# MCU_PADCFG_CTRL0_CFG0 register map
Vendor: Texas Instruments
Peripheral module from a debugger description file (folder J722S).
Registers are 32-bit, read-only, reset 0x0 unless marked. A register's access mark holds for its fields unless they carry their own. Offsets are as the file gives them; lines under a group give offsets from that group; [hi:lo] are bit positions; {n}, {i} and the like mark numbered series; 'fields as' and 'values as' point back to an identical list; <NAME> marks a mode.

## MCU_PADCFG_CTRL0_CFG0
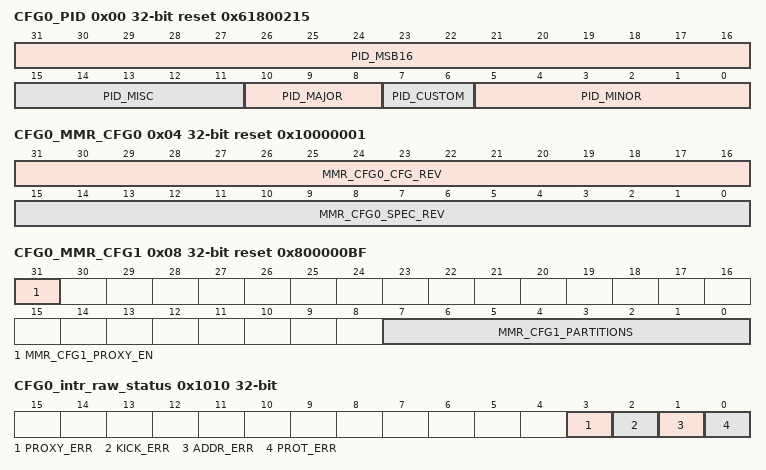
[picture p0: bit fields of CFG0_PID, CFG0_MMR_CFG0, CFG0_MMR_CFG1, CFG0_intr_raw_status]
0x00 CFG0_PID reset 0x61800215
  [31:16] PID_MSB16, [15:11] PID_MISC, [10:8] PID_MAJOR, [7:6] PID_CUSTOM, [5:0] PID_MINOR
0x04 CFG0_MMR_CFG0 reset 0x10000001
  [31:16] MMR_CFG0_CFG_REV — Major configuration release
  [15:0] MMR_CFG0_SPEC_REV — Minor spec-only revision. Doesn't change RTL release
0x08 CFG0_MMR_CFG1 reset 0x800000BF
  [31] MMR_CFG1_PROXY_EN — Proxy addressing enabled
  [7:0] MMR_CFG1_PARTITIONS — Indicates present partitions
0x1008 CFG0_LOCK0_KICK0 rw
  [31:0] LOCK0_KICK0 — - KICK0 component
0x100C CFG0_LOCK0_KICK1 rw
  [31:0] LOCK0_KICK1 — - KICK1 component
0x1010 CFG0_intr_raw_status access not given
  [3] PROXY_ERR — Proxy0 access violation error. Raw status is read. Write a 1 to set the status. Writing a 0 has no effect. (access R/W1TS)
  [2] KICK_ERR — Kick access violation error. Raw status is read. Write a 1 to set the status. Writing a 0 has no effect. (access R/W1TS)
  [1] ADDR_ERR — Addressing violation error. Raw status is read. Write a 1 to set the status. Writing a 0 has no effect. (access R/W1TS)
  [0] PROT_ERR — Protection violation error. Raw status is read. Write a 1 to set the status. Writing a 0 has no effect. (access R/W1TS)
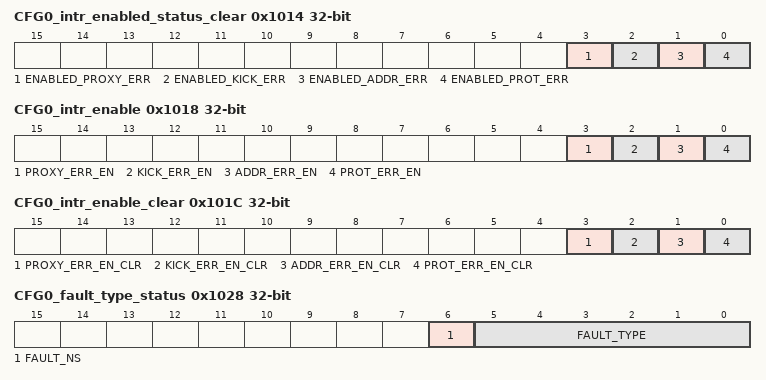
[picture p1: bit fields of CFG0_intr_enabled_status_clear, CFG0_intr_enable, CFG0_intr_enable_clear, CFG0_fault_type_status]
0x1014 CFG0_intr_enabled_status_clear access not given
  [3] ENABLED_PROXY_ERR — Proxy0 access violation error. Enabled status is read. Write a 1 to clear the status. Writing a 0 has no effect. (access R/W1TC)
  [2] ENABLED_KICK_ERR — Kick access violation error. Enabled status is read. Write a 1 to clear the status. Writing a 0 has no effect. (access R/W1TC)
  [1] ENABLED_ADDR_ERR — Addressing violation error. Enabled status is read. Write a 1 to clear the status. Writing a 0 has no effect. (access R/W1TC)
  [0] ENABLED_PROT_ERR — Protection violation error. Enabled status is read. Write a 1 to clear the status. Writing a 0 has no effect. (access R/W1TC)
0x1018 CFG0_intr_enable access not given
  [3] PROXY_ERR_EN — Proxy0 access violation error enable. Write a 1 to set the enable. Writing a 0 has no effect. (access R/W1TS)
  [2] KICK_ERR_EN — Kick access violation error enable. Write a 1 to set the enable. Writing a 0 has no effect. (access R/W1TS)
  [1] ADDR_ERR_EN — Addressing violation error enable. Write a 1 to set the enable. Writing a 0 has no effect. (access R/W1TS)
  [0] PROT_ERR_EN — Protection violation error enable. Write a 1 to set the enable. Writing a 0 has no effect. (access R/W1TS)
0x101C CFG0_intr_enable_clear access not given
  [3] PROXY_ERR_EN_CLR — Proxy0 access violation error enable clear. Write a 1 to clear the enable. Writing a 0 has no effect. (access R/W1TC)
  [2] KICK_ERR_EN_CLR — Kick access violation error enable clear. Write a 1 to clear the enable. Writing a 0 has no effect. (access R/W1TC)
  [1] ADDR_ERR_EN_CLR — Addressing violation error enable clear. Write a 1 to clear the enable. Writing a 0 has no effect. (access R/W1TC)
  [0] PROT_ERR_EN_CLR — Protection violation error enable clear. Write a 1 to clear the enable. Writing a 0 has no effect. (access R/W1TC)
0x1020 CFG0_eoi rw
  [7:0] EOI_VECTOR — EOI vector value. Write this with interrupt distribution value in the chip.
0x1024 CFG0_fault_address
  [31:0] FAULT_ADDR — Fault Address.
0x1028 CFG0_fault_type_status
  [6] FAULT_NS — Non-secure access.
  [5:0] FAULT_TYPE — Fault Type 10_0000 = Supervisor read fault - priv = 1 dir = 1 dtype != 1 01_0000 = Supervisor write fault - priv = 1 dir = 0 00_1000 = Supervisor execute fault - priv = 1 dir = 1 dtype = 1 00_0100 = User read fault - priv = 0 dir = 1 dtype = 1 00_0010 = User write fault - priv = 0 dir = 0 00_0001 = User execute fault - priv = 0 dir = 1 dtype = 1 00_0000 = No fault
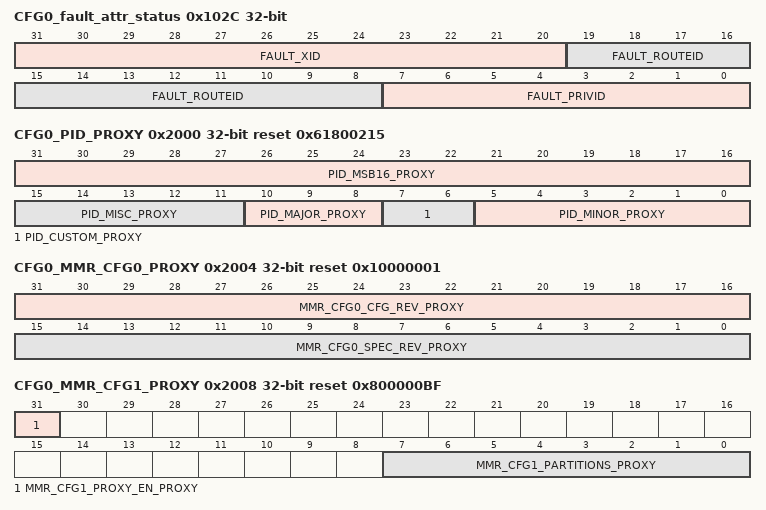
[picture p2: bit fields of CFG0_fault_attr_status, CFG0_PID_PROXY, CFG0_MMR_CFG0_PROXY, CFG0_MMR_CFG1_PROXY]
0x102C CFG0_fault_attr_status
  [31:20] FAULT_XID — XID.
  [19:8] FAULT_ROUTEID — Route ID.
  [7:0] FAULT_PRIVID — Privilege ID.
0x1030 CFG0_fault_clear wo
  [0] FAULT_CLR — Fault clear. Writing a 1 clears the current fault. Writing a 0 has no effect.
0x1100 CFG0_CLAIMREG_P0_R0_READONLY
  [31:0] CLAIMREG_P0_R0_READONLY — Claim bits for Partition 0
0x2000 CFG0_PID_PROXY reset 0x61800215
  [31:16] PID_MSB16_PROXY, [15:11] PID_MISC_PROXY, [10:8] PID_MAJOR_PROXY, [7:6] PID_CUSTOM_PROXY, [5:0] PID_MINOR_PROXY
0x2004 CFG0_MMR_CFG0_PROXY reset 0x10000001
  [31:16] MMR_CFG0_CFG_REV_PROXY — Major configuration release
  [15:0] MMR_CFG0_SPEC_REV_PROXY — Minor spec-only revision. Doesn't change RTL release
0x2008 CFG0_MMR_CFG1_PROXY reset 0x800000BF
  [31] MMR_CFG1_PROXY_EN_PROXY — Proxy addressing enabled
  [7:0] MMR_CFG1_PARTITIONS_PROXY — Indicates present partitions
0x3008 CFG0_LOCK0_KICK0_PROXY rw
  [31:0] LOCK0_KICK0_PROXY — - KICK0 component
0x300C CFG0_LOCK0_KICK1_PROXY rw
  [31:0] LOCK0_KICK1_PROXY — - KICK1 component
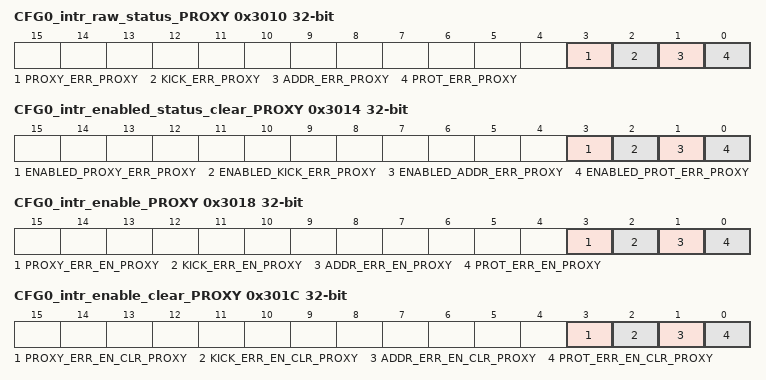
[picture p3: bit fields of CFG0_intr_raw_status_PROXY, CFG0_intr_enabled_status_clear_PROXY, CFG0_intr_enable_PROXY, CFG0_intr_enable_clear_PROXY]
0x3010 CFG0_intr_raw_status_PROXY access not given
  [3] PROXY_ERR_PROXY — Proxy0 access violation error. Raw status is read. Write a 1 to set the status. Writing a 0 has no effect. (access R/W1TS)
  [2] KICK_ERR_PROXY — Kick access violation error. Raw status is read. Write a 1 to set the status. Writing a 0 has no effect. (access R/W1TS)
  [1] ADDR_ERR_PROXY — Addressing violation error. Raw status is read. Write a 1 to set the status. Writing a 0 has no effect. (access R/W1TS)
  [0] PROT_ERR_PROXY — Protection violation error. Raw status is read. Write a 1 to set the status. Writing a 0 has no effect. (access R/W1TS)
0x3014 CFG0_intr_enabled_status_clear_PROXY access not given
  [3] ENABLED_PROXY_ERR_PROXY — Proxy0 access violation error. Enabled status is read. Write a 1 to clear the status. Writing a 0 has no effect. (access R/W1TC)
  [2] ENABLED_KICK_ERR_PROXY — Kick access violation error. Enabled status is read. Write a 1 to clear the status. Writing a 0 has no effect. (access R/W1TC)
  [1] ENABLED_ADDR_ERR_PROXY — Addressing violation error. Enabled status is read. Write a 1 to clear the status. Writing a 0 has no effect. (access R/W1TC)
  [0] ENABLED_PROT_ERR_PROXY — Protection violation error. Enabled status is read. Write a 1 to clear the status. Writing a 0 has no effect. (access R/W1TC)
0x3018 CFG0_intr_enable_PROXY access not given
  [3] PROXY_ERR_EN_PROXY — Proxy0 access violation error enable. Write a 1 to set the enable. Writing a 0 has no effect. (access R/W1TS)
  [2] KICK_ERR_EN_PROXY — Kick access violation error enable. Write a 1 to set the enable. Writing a 0 has no effect. (access R/W1TS)
  [1] ADDR_ERR_EN_PROXY — Addressing violation error enable. Write a 1 to set the enable. Writing a 0 has no effect. (access R/W1TS)
  [0] PROT_ERR_EN_PROXY — Protection violation error enable. Write a 1 to set the enable. Writing a 0 has no effect. (access R/W1TS)
0x301C CFG0_intr_enable_clear_PROXY access not given
  [3] PROXY_ERR_EN_CLR_PROXY — Proxy0 access violation error enable clear. Write a 1 to clear the enable. Writing a 0 has no effect. (access R/W1TC)
  [2] KICK_ERR_EN_CLR_PROXY — Kick access violation error enable clear. Write a 1 to clear the enable. Writing a 0 has no effect. (access R/W1TC)
  [1] ADDR_ERR_EN_CLR_PROXY — Addressing violation error enable clear. Write a 1 to clear the enable. Writing a 0 has no effect. (access R/W1TC)
  [0] PROT_ERR_EN_CLR_PROXY — Protection violation error enable clear. Write a 1 to clear the enable. Writing a 0 has no effect. (access R/W1TC)
0x3020 CFG0_eoi_PROXY rw
  [7:0] EOI_VECTOR_PROXY — EOI vector value. Write this with interrupt distribution value in the chip.
0x3024 CFG0_fault_address_PROXY
  [31:0] FAULT_ADDR_PROXY — Fault Address.
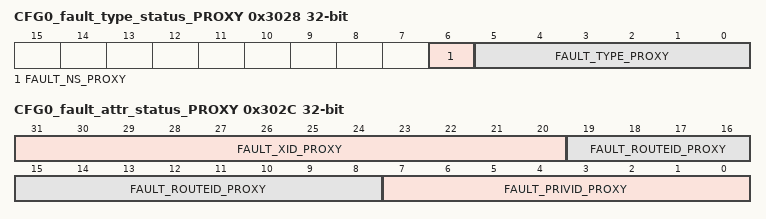
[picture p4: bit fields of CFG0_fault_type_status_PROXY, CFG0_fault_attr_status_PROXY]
0x3028 CFG0_fault_type_status_PROXY
  [6] FAULT_NS_PROXY — Non-secure access.
  [5:0] FAULT_TYPE_PROXY — Fault Type 10_0000 = Supervisor read fault - priv = 1 dir = 1 dtype != 1 01_0000 = Supervisor write fault - priv = 1 dir = 0 00_1000 = Supervisor execute fault - priv = 1 dir = 1 dtype = 1 00_0100 = User read fault - priv = 0 dir = 1 dtype = 1 00_0010 = User write fault - priv = 0 dir = 0 00_0001 = User execute fault - priv = 0 dir = 1 dtype = 1 00_0000 = No fault
0x302C CFG0_fault_attr_status_PROXY
  [31:20] FAULT_XID_PROXY — XID.
  [19:8] FAULT_ROUTEID_PROXY — Route ID.
  [7:0] FAULT_PRIVID_PROXY — Privilege ID.
0x3030 CFG0_fault_clear_PROXY wo
  [0] FAULT_CLR_PROXY — Fault clear. Writing a 1 clears the current fault. Writing a 0 has no effect.
0x3100 CFG0_CLAIMREG_P0_R0 rw
  [31:0] CLAIMREG_P0_R0 — Claim bits for Partition 0
0x5008 CFG0_LOCK1_KICK0 rw
  [31:0] LOCK1_KICK0 — - KICK0 component
0x500C CFG0_LOCK1_KICK1 rw
  [31:0] LOCK1_KICK1 — - KICK1 component
0x5100 CFG0_CLAIMREG_P1_R0_READONLY
  [31:0] CLAIMREG_P1_R0_READONLY — Claim bits for Partition 1
0x5104 CFG0_CLAIMREG_P1_R1_READONLY
  [31:0] CLAIMREG_P1_R1_READONLY — Claim bits for Partition 1
0x7008 CFG0_LOCK1_KICK0_PROXY rw
  [31:0] LOCK1_KICK0_PROXY — - KICK0 component
0x700C CFG0_LOCK1_KICK1_PROXY rw
  [31:0] LOCK1_KICK1_PROXY — - KICK1 component
0x7100 CFG0_CLAIMREG_P1_R0 rw
  [31:0] CLAIMREG_P1_R0 — Claim bits for Partition 1
0x7104 CFG0_CLAIMREG_P1_R1 rw
  [31:0] CLAIMREG_P1_R1 — Claim bits for Partition 1
